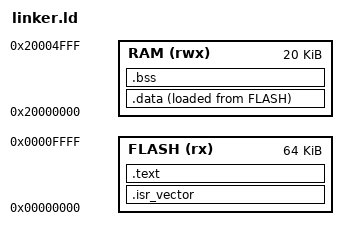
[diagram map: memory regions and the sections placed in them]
ENTRY(Reset_Handler)

MEMORY
{
    FLASH (rx) : ORIGIN = 0x00000000, LENGTH = 64K
    RAM   (rwx): ORIGIN = 0x20000000, LENGTH = 20K
}

_estack = ORIGIN(RAM) + LENGTH(RAM);

SECTIONS
{
    /* Vector table 放在 FLASH 開頭 */
    .isr_vector : {
        KEEP(*(.isr_vector))
    } > FLASH

    .text : {
        *(.text*)
        *(.rodata*)
    } > FLASH

    .data : {
        *(.data*)
    } > RAM AT > FLASH

    .bss : {
        *(.bss*)
        *(COMMON)
    } > RAM
}
